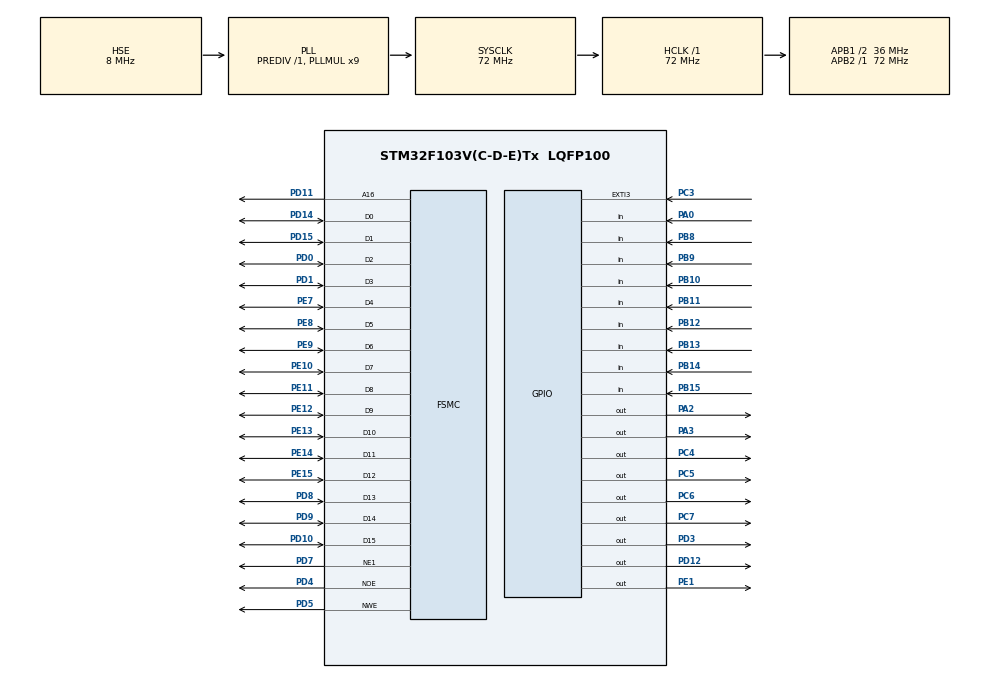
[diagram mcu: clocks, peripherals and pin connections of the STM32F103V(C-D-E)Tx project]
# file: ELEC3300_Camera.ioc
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Mcu.Family=STM32F1
Mcu.Name=STM32F103V(C-D-E)Tx
Mcu.Package=LQFP100
NVIC.EXTI3_IRQn=true\:0\:0\:false\:false\:true\:true\:true
NVIC.PriorityGroup=NVIC_PRIORITYGROUP_4
OSC_IN.Mode=HSE-External-Oscillator
OSC_IN.Signal=RCC_OSC_IN
OSC_OUT.Mode=HSE-External-Oscillator
OSC_OUT.Signal=RCC_OSC_OUT
PA0-WKUP.Signal=GPIO_Input
PA13.Mode=Serial_Wire
PA13.Signal=SYS_JTMS-SWDIO
PA14.Mode=Serial_Wire
PA14.Signal=SYS_JTCK-SWCLK
PA2.GPIO_Speed=GPIO_SPEED_FREQ_HIGH
PA2.Signal=GPIO_Output
PA3.GPIO_Speed=GPIO_SPEED_FREQ_HIGH
PA3.Signal=GPIO_Output
PB10.Signal=GPIO_Input
PB11.Signal=GPIO_Input
PB12.Signal=GPIO_Input
PB13.Signal=GPIO_Input
PB14.Signal=GPIO_Input
PB15.Signal=GPIO_Input
PB8.Signal=GPIO_Input
PB9.Signal=GPIO_Input
PC14-OSC32_IN.Mode=LSE-External-Oscillator
PC14-OSC32_IN.Signal=RCC_OSC32_IN
PC15-OSC32_OUT.Mode=LSE-External-Oscillator
PC15-OSC32_OUT.Signal=RCC_OSC32_OUT
PC3.GPIO_ModeDefaultEXTI=GPIO_MODE_IT_FALLING
PC3.Signal=GPXTI3
PC4.GPIO_Speed=GPIO_SPEED_FREQ_HIGH
PC4.Signal=GPIO_Output
PC5.GPIO_Speed=GPIO_SPEED_FREQ_HIGH
PC5.Signal=GPIO_Output
PC6.GPIO_ModeDefaultOutputPP=GPIO_MODE_OUTPUT_OD
PC6.GPIO_PuPd=GPIO_NOPULL
PC6.GPIO_Speed=GPIO_SPEED_FREQ_HIGH
PC6.Signal=GPIO_Output
PC7.GPIO_ModeDefaultOutputPP=GPIO_MODE_OUTPUT_OD
PC7.GPIO_Speed=GPIO_SPEED_FREQ_HIGH
PC7.Signal=GPIO_Output
PD0.Mode=16b-d1
PD0.Signal=FSMC_D2
PD1.Mode=16b-d1
PD1.Signal=FSMC_D3
PD10.Mode=16b-d1
PD10.Signal=FSMC_D15
PD11.Mode=A16_1
PD11.Signal=FSMC_A16
PD12.GPIO_Speed=GPIO_SPEED_FREQ_HIGH
PD12.PinState=GPIO_PIN_RESET
PD12.Signal=GPIO_Output
PD14.Mode=16b-d1
PD14.Signal=FSMC_D0
PD15.Mode=16b-d1
PD15.Signal=FSMC_D1
PD3.GPIO_Speed=GPIO_SPEED_FREQ_HIGH
PD3.Signal=GPIO_Output
PD4.Mode=Lcd1
PD4.Signal=FSMC_NOE
PD5.Mode=Lcd1
PD5.Signal=FSMC_NWE
PD7.Mode=NorPsramChipSelect1_1
PD7.Signal=FSMC_NE1
PD8.Mode=16b-d1
PD8.Signal=FSMC_D13
PD9.Mode=16b-d1
PD9.Signal=FSMC_D14
PE1.GPIO_Speed=GPIO_SPEED_FREQ_HIGH
PE1.PinState=GPIO_PIN_RESET
PE1.Signal=GPIO_Output
PE10.Mode=16b-d1
PE10.Signal=FSMC_D7
PE11.Mode=16b-d1
PE11.Signal=FSMC_D8
PE12.Mode=16b-d1
PE12.Signal=FSMC_D9
PE13.Mode=16b-d1
PE13.Signal=FSMC_D10
PE14.Mode=16b-d1
PE14.Signal=FSMC_D11
PE15.Mode=16b-d1
PE15.Signal=FSMC_D12
PE7.Mode=16b-d1
PE7.Signal=FSMC_D4
PE8.Mode=16b-d1
PE8.Signal=FSMC_D5
PE9.Mode=16b-d1
PE9.Signal=FSMC_D6
ProjectManager.HeapSize=0x200
ProjectManager.StackSize=0x400
ProjectManager.TargetToolchain=MDK-ARM V5.32
RCC.AHBFreq_Value=72000000
RCC.APB1CLKDivider=RCC_HCLK_DIV2
RCC.APB1Freq_Value=36000000
RCC.APB1TimFreq_Value=72000000
RCC.APB2Freq_Value=72000000
RCC.APB2TimFreq_Value=72000000
RCC.HCLKFreq_Value=72000000
RCC.PLLMUL=RCC_PLL_MUL9
RCC.PLLSourceVirtual=RCC_PLLSOURCE_HSE
RCC.SYSCLKFreq_VALUE=72000000
RCC.SYSCLKSource=RCC_SYSCLKSOURCE_PLLCLK
RCC.USBFreq_Value=72000000
board=custom

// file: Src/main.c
/* USER CODE BEGIN Header */
/**
  ******************************************************************************
  * @file           : main.c
  * @brief          : Main program body
  ******************************************************************************
  * @attention
  *
  * <h2><center>&copy; Copyright (c) 2019 STMicroelectronics.
  * All rights reserved.</center></h2>
  *
  * This software component is licensed by ST under BSD 3-Clause license,
  * the "License"; You may not use this file except in compliance with the
  * License. You may obtain a copy of the License at:
  *                        opensource.org/licenses/BSD-3-Clause
  *
  ******************************************************************************
  */
/* USER CODE END Header */

#include "main.h"

/* USER CODE BEGIN Includes */
#include "lcd.h"
#include "bsp_ov7725.h"
#include "bsp_sccb.h"

/* USER CODE END Includes */

SRAM_HandleTypeDef hsram1;

void SystemClock_Config(void);
static void MX_GPIO_Init(void);
static void MX_FSMC_Init(void);
/* USER CODE BEGIN PFP */
volatile uint8_t Ov7725_vsync ;
/* USER CODE END PFP */

int main(void)
{

  /* MCU Configuration--------------------------------------------------------*/

  /* Reset of all peripherals, Initializes the Flash interface and the Systick. */
  HAL_Init();

  /* Configure the system clock */
  SystemClock_Config();

  /* Initialize all configured peripherals */
  MX_GPIO_Init();
  MX_FSMC_Init();
  /* USER CODE BEGIN 2 */
	LCD_INIT();
  /* USER CODE END 2 */

  /* Infinite loop */
  /* USER CODE BEGIN WHILE */

	while(Ov7725_Init() != SUCCESS); //initialize camera ov7725; if any error, loop forever
	Ov7725_vsync = 0;   //for detecting if camera finish capturing; if yes, it becomes 2 as detecting two failing edge in VSYNC

  while (1)
  {
		if (Ov7725_vsync == 2){ //finish capturing
			if(HAL_GPIO_ReadPin(GPIOA, GPIO_PIN_0) == SET){ //if KEY1 press, take a photo
				FIFO_PREPARE; //ready for FIFO
				ImagDisp();			//function in bsp_ov7725.c
				Ov7725_vsync = 0;   //reset to 0 for detect next photo
			}
		}
    /* USER CODE END WHILE */

  }
}

void SystemClock_Config(void)
{
  RCC_OscInitTypeDef RCC_OscInitStruct = {0};
  RCC_ClkInitTypeDef RCC_ClkInitStruct = {0};

  /** Initializes the CPU, AHB and APB busses clocks
  */
  RCC_OscInitStruct.OscillatorType = RCC_OSCILLATORTYPE_HSE;
  RCC_OscInitStruct.HSEState = RCC_HSE_ON;
  RCC_OscInitStruct.HSEPredivValue = RCC_HSE_PREDIV_DIV1;
  RCC_OscInitStruct.HSIState = RCC_HSI_ON;
  RCC_OscInitStruct.PLL.PLLState = RCC_PLL_ON;
  RCC_OscInitStruct.PLL.PLLSource = RCC_PLLSOURCE_HSE;
  RCC_OscInitStruct.PLL.PLLMUL = RCC_PLL_MUL9;
  if (HAL_RCC_OscConfig(&RCC_OscInitStruct) != HAL_OK)
  {
    Error_Handler();
  }
  /** Initializes the CPU, AHB and APB busses clocks
  */
  RCC_ClkInitStruct.ClockType = RCC_CLOCKTYPE_HCLK|RCC_CLOCKTYPE_SYSCLK
                              |RCC_CLOCKTYPE_PCLK1|RCC_CLOCKTYPE_PCLK2;
  RCC_ClkInitStruct.SYSCLKSource = RCC_SYSCLKSOURCE_PLLCLK;
  RCC_ClkInitStruct.AHBCLKDivider = RCC_SYSCLK_DIV1;
  RCC_ClkInitStruct.APB1CLKDivider = RCC_HCLK_DIV2;
  RCC_ClkInitStruct.APB2CLKDivider = RCC_HCLK_DIV1;

  if (HAL_RCC_ClockConfig(&RCC_ClkInitStruct, FLASH_LATENCY_2) != HAL_OK)
  {
    Error_Handler();
  }
}

static void MX_GPIO_Init(void)
{
  GPIO_InitTypeDef GPIO_InitStruct = {0};

  /* GPIO Ports Clock Enable */
  __HAL_RCC_GPIOC_CLK_ENABLE();
  __HAL_RCC_GPIOA_CLK_ENABLE();
  __HAL_RCC_GPIOE_CLK_ENABLE();
  __HAL_RCC_GPIOB_CLK_ENABLE();
  __HAL_RCC_GPIOD_CLK_ENABLE();

  /*Configure GPIO pin Output Level */
  HAL_GPIO_WritePin(GPIOA, GPIO_PIN_2|GPIO_PIN_3, GPIO_PIN_RESET);

  /*Configure GPIO pin Output Level */
  HAL_GPIO_WritePin(GPIOC, GPIO_PIN_4|GPIO_PIN_5|GPIO_PIN_6|GPIO_PIN_7, GPIO_PIN_RESET);

  /*Configure GPIO pin Output Level */
  HAL_GPIO_WritePin(GPIOD, GPIO_PIN_12|GPIO_PIN_3, GPIO_PIN_RESET);

  /*Configure GPIO pin Output Level */
  HAL_GPIO_WritePin(GPIOE, GPIO_PIN_1, GPIO_PIN_RESET);

  /*Configure GPIO pin : PC3 */
  GPIO_InitStruct.Pin = GPIO_PIN_3;
  GPIO_InitStruct.Mode = GPIO_MODE_IT_FALLING;
  GPIO_InitStruct.Pull = GPIO_NOPULL;
  HAL_GPIO_Init(GPIOC, &GPIO_InitStruct);

  /*Configure GPIO pin : PA0 */
  GPIO_InitStruct.Pin = GPIO_PIN_0;
  GPIO_InitStruct.Mode = GPIO_MODE_INPUT;
  GPIO_InitStruct.Pull = GPIO_NOPULL;
  HAL_GPIO_Init(GPIOA, &GPIO_InitStruct);

  /*Configure GPIO pins : PA2 PA3 */
  GPIO_InitStruct.Pin = GPIO_PIN_2|GPIO_PIN_3;
  GPIO_InitStruct.Mode = GPIO_MODE_OUTPUT_PP;
  GPIO_InitStruct.Pull = GPIO_NOPULL;
  GPIO_InitStruct.Speed = GPIO_SPEED_FREQ_HIGH;
  HAL_GPIO_Init(GPIOA, &GPIO_InitStruct);

  /*Configure GPIO pins : PC4 PC5 */
  GPIO_InitStruct.Pin = GPIO_PIN_4|GPIO_PIN_5;
  GPIO_InitStruct.Mode = GPIO_MODE_OUTPUT_PP;
  GPIO_InitStruct.Pull = GPIO_NOPULL;
  GPIO_InitStruct.Speed = GPIO_SPEED_FREQ_HIGH;
  HAL_GPIO_Init(GPIOC, &GPIO_InitStruct);

  /*Configure GPIO pins : PB10 PB11 PB12 PB13
                           PB14 PB15 PB8 PB9 */
  GPIO_InitStruct.Pin = GPIO_PIN_10|GPIO_PIN_11|GPIO_PIN_12|GPIO_PIN_13
                          |GPIO_PIN_14|GPIO_PIN_15|GPIO_PIN_8|GPIO_PIN_9;
  GPIO_InitStruct.Mode = GPIO_MODE_INPUT;
  GPIO_InitStruct.Pull = GPIO_NOPULL;
  HAL_GPIO_Init(GPIOB, &GPIO_InitStruct);

  /*Configure GPIO pins : PD12 PD3 */
  GPIO_InitStruct.Pin = GPIO_PIN_12|GPIO_PIN_3;
  GPIO_InitStruct.Mode = GPIO_MODE_OUTPUT_PP;
  GPIO_InitStruct.Pull = GPIO_NOPULL;
  GPIO_InitStruct.Speed = GPIO_SPEED_FREQ_HIGH;
  HAL_GPIO_Init(GPIOD, &GPIO_InitStruct);

  /*Configure GPIO pins : PC6 PC7 */
  GPIO_InitStruct.Pin = GPIO_PIN_6|GPIO_PIN_7;
  GPIO_InitStruct.Mode = GPIO_MODE_OUTPUT_OD;
  GPIO_InitStruct.Pull = GPIO_NOPULL;
  GPIO_InitStruct.Speed = GPIO_SPEED_FREQ_HIGH;
  HAL_GPIO_Init(GPIOC, &GPIO_InitStruct);

  /*Configure GPIO pin : PE1 */
  GPIO_InitStruct.Pin = GPIO_PIN_1;
  GPIO_InitStruct.Mode = GPIO_MODE_OUTPUT_PP;
  GPIO_InitStruct.Pull = GPIO_NOPULL;
  GPIO_InitStruct.Speed = GPIO_SPEED_FREQ_HIGH;
  HAL_GPIO_Init(GPIOE, &GPIO_InitStruct);

  /* EXTI interrupt init*/
  HAL_NVIC_SetPriority(EXTI3_IRQn, 0, 0);
  HAL_NVIC_EnableIRQ(EXTI3_IRQn);

}

/* FSMC initialization function */
static void MX_FSMC_Init(void)
{

  FSMC_NORSRAM_TimingTypeDef Timing = {0};

  /** Perform the SRAM1 memory initialization sequence
  */
  hsram1.Instance = FSMC_NORSRAM_DEVICE;
  hsram1.Extended = FSMC_NORSRAM_EXTENDED_DEVICE;
  /* hsram1.Init */
  hsram1.Init.NSBank = FSMC_NORSRAM_BANK1;
  hsram1.Init.DataAddressMux = FSMC_DATA_ADDRESS_MUX_DISABLE;
  hsram1.Init.MemoryType = FSMC_MEMORY_TYPE_SRAM;
  hsram1.Init.MemoryDataWidth = FSMC_NORSRAM_MEM_BUS_WIDTH_16;
  hsram1.Init.BurstAccessMode = FSMC_BURST_ACCESS_MODE_DISABLE;
  hsram1.Init.WaitSignalPolarity = FSMC_WAIT_SIGNAL_POLARITY_LOW;
  hsram1.Init.WrapMode = FSMC_WRAP_MODE_DISABLE;
  hsram1.Init.WaitSignalActive = FSMC_WAIT_TIMING_BEFORE_WS;
  hsram1.Init.WriteOperation = FSMC_WRITE_OPERATION_ENABLE;
  hsram1.Init.WaitSignal = FSMC_WAIT_SIGNAL_DISABLE;
  hsram1.Init.ExtendedMode = FSMC_EXTENDED_MODE_DISABLE;
  hsram1.Init.AsynchronousWait = FSMC_ASYNCHRONOUS_WAIT_DISABLE;
  hsram1.Init.WriteBurst = FSMC_WRITE_BURST_DISABLE;
  /* Timing */
  Timing.AddressSetupTime = 15;
  Timing.AddressHoldTime = 15;
  Timing.DataSetupTime = 255;
  Timing.BusTurnAroundDuration = 15;
  Timing.CLKDivision = 16;
  Timing.DataLatency = 17;
  Timing.AccessMode = FSMC_ACCESS_MODE_A;
  /* ExtTiming */

  if (HAL_SRAM_Init(&hsram1, &Timing, NULL) != HAL_OK)
  {
    Error_Handler( );
  }

  /** Disconnect NADV
  */

  __HAL_AFIO_FSMCNADV_DISCONNECTED();

}

void Error_Handler(void)
{
}

/************************ (C) COPYRIGHT STMicroelectronics *****END OF FILE****/
